# STM32H7S3xx register map
File version: 1.0
Registers are 32-bit, read-write, reset 0x0 unless marked. A register's access mark holds for its fields unless they carry their own. Offsets are from the block's base; [hi:lo] are bit positions; {n}, {i} and the like mark numbered series.

## PSSI
Base 0x48000400
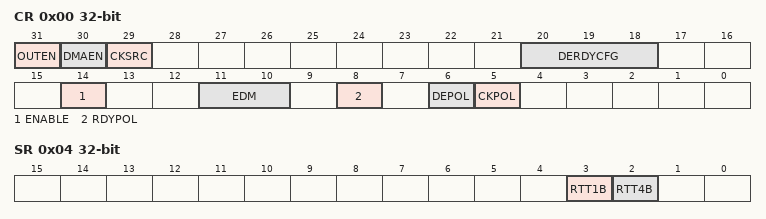
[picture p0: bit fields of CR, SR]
0x00 CR — PSSI control register
  [31] OUTEN — Data direction selection
  [30] DMAEN — DMA enable
  [29] CKSRC — Clock source
  [20:18] DERDYCFG — Data enable and ready configuration
  [14] ENABLE — PSSI enable
  [11:10] EDM — Extended data mode
  [8] RDYPOL — Ready polarity
  [6] DEPOL — Data enable polarity
  [5] CKPOL — Parallel data clock polarity
0x04 SR — PSSI status register
  [3] RTT1B — Ready to transfer one byte
  [2] RTT4B — Ready to transfer four bytes
0x08 RIS — PSSI raw interrupt status register
  [1] OVR_RIS — Data buffer overrun/underrun raw interrupt status
0x0C IER — PSSI interrupt enable register
  [1] OVR_IE — Data buffer overrun/underrun interrupt enable
0x10 MIS — PSSI masked interrupt status register
  [1] OVR_MIS — Data buffer overrun/underrun masked interrupt status
0x14 ICR — PSSI interrupt clear register
  [1] OVR_ISC — Data buffer overrun/underrun interrupt status clear
0x28 DR — PSSI data register
  [31:0] DR — Data register

## DLYB_SDMMC2
Base 0x48002800
Same registers: DLYB_SDMMC1 0x52008000
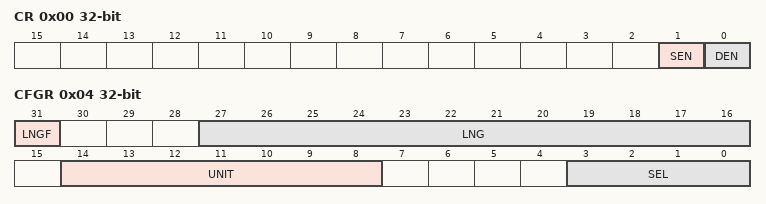
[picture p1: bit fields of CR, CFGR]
0x00 CR — Delay Block Control Register
  [1] SEN — Sampler length enable
  [0] DEN — Delay Block enable
0x04 CFGR — Delay Block Configuration Register
  [31] LNGF — Length valid flag
  [27:16] LNG — Delay line length value[11:0]
  [14:8] UNIT — Delay Defines the delay of a Unit delay cell[6:0]
  [3:0] SEL — Select the phase for the Output clock[3:0]

## CORDIC
Base 0x48004400
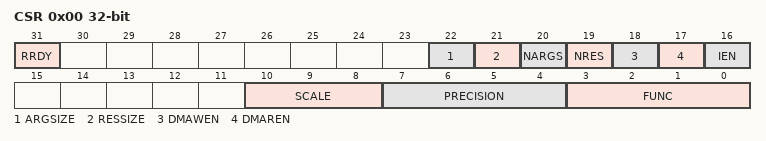
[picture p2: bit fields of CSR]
0x00 CSR — CORDIC Control and Status register
  [31] RRDY — Result Ready Flag
  [22] ARGSIZE — Width of input data
    0=INSIZE_32BITS (32 bits input data size (Q1.31 format)); 1=INSIZE_16BITS (16 bits input data size (Q1.15 format))
  [21] RESSIZE — Width of output data
    0=OUTSIZE_32BITS (32 bits output data size (Q1.31 format)); 1=OUTSIZE_16BITS (16 bits output data size (Q1.15 format))
  [20] NARGS — Number of arguments in RDATA register
    0=NBWRITE_1; 1=NBWRITE_2
  [19] NRES — Number of results in WDATA register
    0=NBREAD_1; 1=NBREAD_2
  [18] DMAWEN — DMA Write channel Enable
  [17] DMAREN — DMA Read channel Enable
  [16] IEN — Interrupt Enable
  [10:8] SCALE — Scaling factor
  [7:4] PRECISION
    1=PRECISION_1CYCLE; {v}=PRECISION_{v}CYCLES (v=2..15)
  [3:0] FUNC — Function
    0=COSINE; 1=SINE; 2=PHASE; 3=MODULUS; 4=ARCTANGENT; 5=HCOSINE (Hyperbolic Cosine); 6=HSINE (Hyperbolic Sine); 7=HARCTANGENT (Hyperbolic Arctangent); 8=NATURALLOG (Natural Logarithm); 9=SQUAREROOT
0x04 WDATA — CORDIC argument register
  [31:0] ARG — Input Argument
0x08 RDATA — CORDIC result register
  [31:0] RES — Output Result

## RNG — Random Number Generator
Base 0x48020000
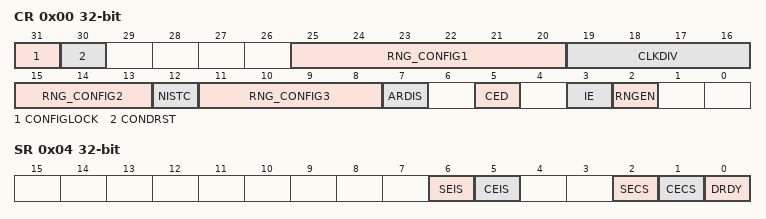
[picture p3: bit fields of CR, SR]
0x00 CR — RNG control register
  [31] CONFIGLOCK
  [30] CONDRST
  [25:20] RNG_CONFIG1
  [19:16] CLKDIV
    0=BY_1 (No clock division); 1=BY_2 (2 RNG clock cycles per internal RNG clock); 2=BY_4 (4 RNG clock cycles per internal RNG clock); 3=BY_8 (8 RNG clock cycles per internal RNG clock); 4=BY_16 (16 RNG clock cycles per internal RNG clock); 5=BY_32 (32 RNG clock cycles per internal RNG clock); 6=BY_64 (64 RNG clock cycles per internal RNG clock); 7=BY_128 (128 RNG clock cycles per internal RNG clock); 8=BY_256 (256 RNG clock cycles per internal RNG clock); 9=BY_512 (512 RNG clock cycles per internal RNG clock); 10=BY_1024 (1024 RNG clock cycles per internal RNG clock); 11=BY_2048 (2048 RNG clock cycles per internal RNG clock); 12=BY_4096 (4096 RNG clock cycles per internal RNG clock); 13=BY_8192 (8192 RNG clock cycles per internal RNG clock); 14=BY_16384 (16384 RNG clock cycles per internal RNG clock); 15=BY_32768 (32768 RNG clock cycles per internal RNG clock)
  [15:13] RNG_CONFIG2
  [12] NISTC
  [11:8] RNG_CONFIG3
  [7] ARDIS
  [5] CED
  [3] IE
  [2] RNGEN
0x04 SR — RNG status register
  [6] SEIS, [5] CEIS, [2] SECS, [1] CECS, [0] DRDY
0x08 DR — RNG data register
0x10 HTCR — RNG health test configuration register
  [31:0] HTCFG
